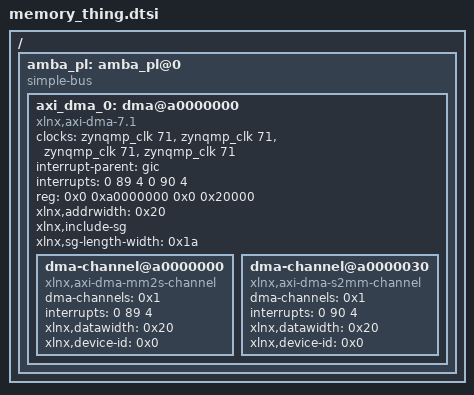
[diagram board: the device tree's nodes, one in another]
/*
 * CAUTION: This file is automatically generated by Xilinx.
 * Version: XSCT 2022.1
 * Today is: Mon Nov  2 20:06:20 2026
 */


/ {
	amba_pl: amba_pl@0 {
		#address-cells = <2>;
		#size-cells = <2>;
		compatible = "simple-bus";
		ranges ;
		axi_dma_0: dma@a0000000 {
			#dma-cells = <1>;
			clock-names = "s_axi_lite_aclk", "m_axi_sg_aclk", "m_axi_mm2s_aclk", "m_axi_s2mm_aclk";
			clocks = <&zynqmp_clk 71>, <&zynqmp_clk 71>, <&zynqmp_clk 71>, <&zynqmp_clk 71>;
			compatible = "xlnx,axi-dma-7.1", "xlnx,axi-dma-1.00.a";
			interrupt-names = "mm2s_introut", "s2mm_introut";
			interrupt-parent = <&gic>;
			interrupts = <0 89 4 0 90 4>;
			reg = <0x0 0xa0000000 0x0 0x20000>;
			xlnx,addrwidth = <0x20>;
			xlnx,include-sg ;
			xlnx,sg-length-width = <0x1a>;
			dma-channel@a0000000 {
				compatible = "xlnx,axi-dma-mm2s-channel";
				dma-channels = <0x1>;
				interrupts = <0 89 4>;
				xlnx,datawidth = <0x20>;
				xlnx,device-id = <0x0>;
			};
			dma-channel@a0000030 {
				compatible = "xlnx,axi-dma-s2mm-channel";
				dma-channels = <0x1>;
				interrupts = <0 90 4>;
				xlnx,datawidth = <0x20>;
				xlnx,device-id = <0x0>;
			};
		};
	};
};
